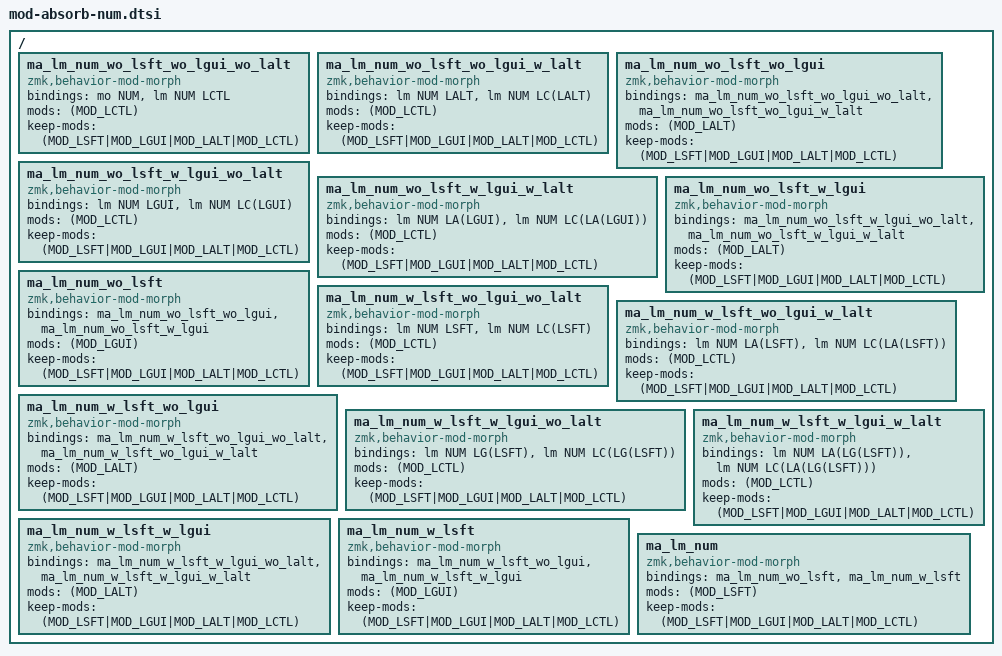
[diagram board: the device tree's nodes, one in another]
/ {
    ma_lm_num_wo_lsft_wo_lgui_wo_lalt: ma_lm_num_wo_lsft_wo_lgui_wo_lalt {
        compatible = "zmk,behavior-mod-morph";
        #binding-cells = <0>;
        bindings = <&mo NUM>, <&lm NUM LCTL>;

        mods = <(MOD_LCTL)>;
        keep-mods = <(MOD_LSFT|MOD_LGUI|MOD_LALT|MOD_LCTL)>;
    };

     ma_lm_num_wo_lsft_wo_lgui_w_lalt: ma_lm_num_wo_lsft_wo_lgui_w_lalt {
        compatible = "zmk,behavior-mod-morph";
        #binding-cells = <0>;
        bindings = <&lm NUM LALT>, <&lm NUM LC(LALT)>;

        mods = <(MOD_LCTL)>;
        keep-mods = <(MOD_LSFT|MOD_LGUI|MOD_LALT|MOD_LCTL)>;
    };

     ma_lm_num_wo_lsft_wo_lgui: ma_lm_num_wo_lsft_wo_lgui {
        compatible = "zmk,behavior-mod-morph";
        #binding-cells = <0>;
        bindings = <&ma_lm_num_wo_lsft_wo_lgui_wo_lalt>, <&ma_lm_num_wo_lsft_wo_lgui_w_lalt>;

        mods = <(MOD_LALT)>;
        keep-mods = <(MOD_LSFT|MOD_LGUI|MOD_LALT|MOD_LCTL)>;
    };

     ma_lm_num_wo_lsft_w_lgui_wo_lalt: ma_lm_num_wo_lsft_w_lgui_wo_lalt {
        compatible = "zmk,behavior-mod-morph";
        #binding-cells = <0>;
        bindings = <&lm NUM LGUI>, <&lm NUM LC(LGUI)>;

        mods = <(MOD_LCTL)>;
        keep-mods = <(MOD_LSFT|MOD_LGUI|MOD_LALT|MOD_LCTL)>;
    };

     ma_lm_num_wo_lsft_w_lgui_w_lalt: ma_lm_num_wo_lsft_w_lgui_w_lalt {
        compatible = "zmk,behavior-mod-morph";
        #binding-cells = <0>;
        bindings = <&lm NUM LA(LGUI)>, <&lm NUM LC(LA(LGUI))>;

        mods = <(MOD_LCTL)>;
        keep-mods = <(MOD_LSFT|MOD_LGUI|MOD_LALT|MOD_LCTL)>;
    };

     ma_lm_num_wo_lsft_w_lgui: ma_lm_num_wo_lsft_w_lgui {
        compatible = "zmk,behavior-mod-morph";
        #binding-cells = <0>;
        bindings = <&ma_lm_num_wo_lsft_w_lgui_wo_lalt>, <&ma_lm_num_wo_lsft_w_lgui_w_lalt>;

        mods = <(MOD_LALT)>;
        keep-mods = <(MOD_LSFT|MOD_LGUI|MOD_LALT|MOD_LCTL)>;
    };

     ma_lm_num_wo_lsft: ma_lm_num_wo_lsft {
        compatible = "zmk,behavior-mod-morph";
        #binding-cells = <0>;
        bindings = <&ma_lm_num_wo_lsft_wo_lgui>, <&ma_lm_num_wo_lsft_w_lgui>;

        mods = <(MOD_LGUI)>;
        keep-mods = <(MOD_LSFT|MOD_LGUI|MOD_LALT|MOD_LCTL)>;
    };

     ma_lm_num_w_lsft_wo_lgui_wo_lalt: ma_lm_num_w_lsft_wo_lgui_wo_lalt {
        compatible = "zmk,behavior-mod-morph";
        #binding-cells = <0>;
        bindings = <&lm NUM LSFT>, <&lm NUM LC(LSFT)>;

        mods = <(MOD_LCTL)>;
        keep-mods = <(MOD_LSFT|MOD_LGUI|MOD_LALT|MOD_LCTL)>;
    };

     ma_lm_num_w_lsft_wo_lgui_w_lalt: ma_lm_num_w_lsft_wo_lgui_w_lalt {
        compatible = "zmk,behavior-mod-morph";
        #binding-cells = <0>;
        bindings = <&lm NUM LA(LSFT)>, <&lm NUM LC(LA(LSFT))>;

        mods = <(MOD_LCTL)>;
        keep-mods = <(MOD_LSFT|MOD_LGUI|MOD_LALT|MOD_LCTL)>;
    };

     ma_lm_num_w_lsft_wo_lgui: ma_lm_num_w_lsft_wo_lgui {
        compatible = "zmk,behavior-mod-morph";
        #binding-cells = <0>;
        bindings = <&ma_lm_num_w_lsft_wo_lgui_wo_lalt>, <&ma_lm_num_w_lsft_wo_lgui_w_lalt>;

        mods = <(MOD_LALT)>;
        keep-mods = <(MOD_LSFT|MOD_LGUI|MOD_LALT|MOD_LCTL)>;
    };

     ma_lm_num_w_lsft_w_lgui_wo_lalt: ma_lm_num_w_lsft_w_lgui_wo_lalt {
        compatible = "zmk,behavior-mod-morph";
        #binding-cells = <0>;
        bindings = <&lm NUM LG(LSFT)>, <&lm NUM LC(LG(LSFT))>;

        mods = <(MOD_LCTL)>;
        keep-mods = <(MOD_LSFT|MOD_LGUI|MOD_LALT|MOD_LCTL)>;
    };

     ma_lm_num_w_lsft_w_lgui_w_lalt: ma_lm_num_w_lsft_w_lgui_w_lalt {
        compatible = "zmk,behavior-mod-morph";
        #binding-cells = <0>;
        bindings = <&lm NUM LA(LG(LSFT))>, <&lm NUM LC(LA(LG(LSFT)))>;

        mods = <(MOD_LCTL)>;
        keep-mods = <(MOD_LSFT|MOD_LGUI|MOD_LALT|MOD_LCTL)>;
    };

     ma_lm_num_w_lsft_w_lgui: ma_lm_num_w_lsft_w_lgui {
        compatible = "zmk,behavior-mod-morph";
        #binding-cells = <0>;
        bindings = <&ma_lm_num_w_lsft_w_lgui_wo_lalt>, <&ma_lm_num_w_lsft_w_lgui_w_lalt>;

        mods = <(MOD_LALT)>;
        keep-mods = <(MOD_LSFT|MOD_LGUI|MOD_LALT|MOD_LCTL)>;
    };

     ma_lm_num_w_lsft: ma_lm_num_w_lsft {
        compatible = "zmk,behavior-mod-morph";
        #binding-cells = <0>;
        bindings = <&ma_lm_num_w_lsft_wo_lgui>, <&ma_lm_num_w_lsft_w_lgui>;

        mods = <(MOD_LGUI)>;
        keep-mods = <(MOD_LSFT|MOD_LGUI|MOD_LALT|MOD_LCTL)>;
    };

     ma_lm_num: ma_lm_num {
        compatible = "zmk,behavior-mod-morph";
        #binding-cells = <0>;
        bindings = <&ma_lm_num_wo_lsft>, <&ma_lm_num_w_lsft>;

        mods = <(MOD_LSFT)>;
        keep-mods = <(MOD_LSFT|MOD_LGUI|MOD_LALT|MOD_LCTL)>;
    };
};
